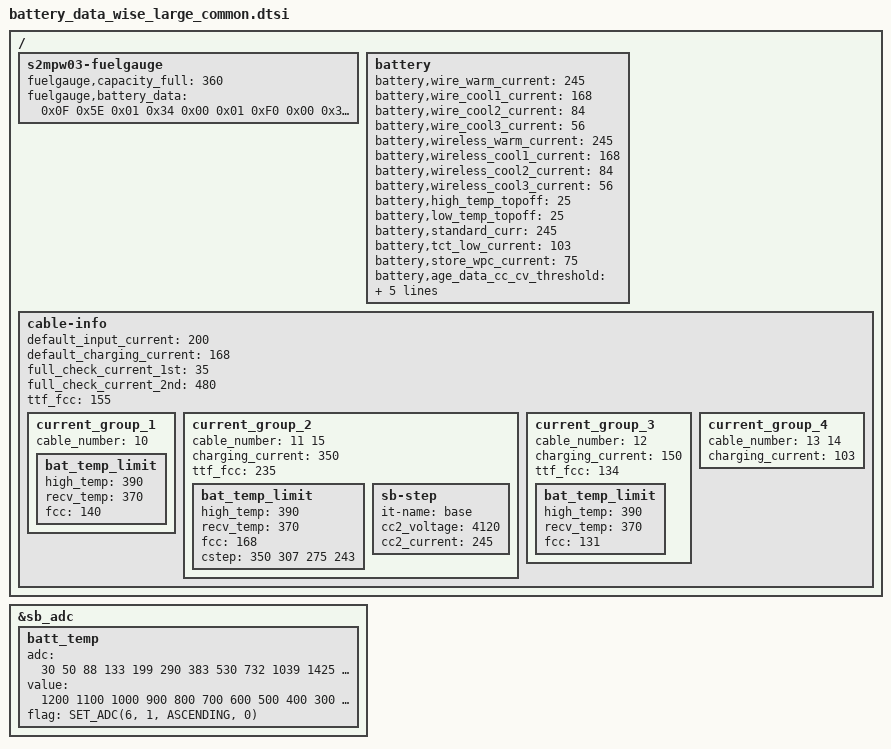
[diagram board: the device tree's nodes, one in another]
/*
 * SAMSUNG EXYNOS5515 board device tree source
 *
 * Copyright (c) 2021 Samsung Electronics Co., Ltd.
 *		http://www.samsung.com
 *
 * This program is free software; you can redistribute it and/or modify
 * it under the terms of the GNU General Public License version 2 as
 * published by the Free Software Foundation.
 */

#include "battery_data_wise_common.dtsi"

&sb_adc {
	batt_temp {
		adc = <
			30 50 88 133 199 290 383 530 732 1039
			1425 1871 2365 2853 3324
			>;

		value = <
			1200 1100 1000 900 800 700 600 500 400 300
			200 100 0 (-100) (-200)
			>;

		flag = <SET_ADC(6, 1, ASCENDING, 0)>;
	};
};

/ {
	fragment@battery {
		target-path = "/";
		__overlay__ {
			s2mpw03-fuelgauge {
				fuelgauge,capacity_full = <360>;

				fuelgauge,battery_data = /bits/ 8 <
					/* 4.42V */					
					/* table1 */
					0x0F 0x5E 0x01 0x34 0x00
					/* table2 */
					0x01 0xF0 0x00
					/* model_param1 */
					0x30 0x0B 0xD6 0x0A 0x7C 0x0A 0x33 0x0A 0xBB 0x09
					0x45 0x09 0xD5 0x08 0x6C 0x08 0x0A 0x08 0xA8 0x07
					0x3B 0x07 0xF8 0x06 0xBB 0x06 0x8F 0x06 0x6B 0x06
					0x4C 0x06 0x22 0x06 0xF7 0x05 0xC5 0x05 0x91 0x05
					0x6D 0x05 0xD8 0x02 0x66 0x08 0x00 0x08 0x9A 0x07
					0x33 0x07 0xCD 0x06 0x66 0x06 0x00 0x06 0x9A 0x05
					0x33 0x05 0xCD 0x04 0x66 0x04 0x00 0x04 0x9A 0x03
					0x33 0x03 0xCD 0x02 0x66 0x02 0x00 0x02 0x9A 0x01
					0x33 0x01 0xCD 0x00 0x66 0x00 0x00 0x00
					/* model_param2 */
					0xFF 0xFF 0xCB 0xCD 0xC9 0xC6 0xC4 0xC1 0xBF 0xBE
					0xC3 0xE4 0xC8 0xC8 0xC6 0xC0 0xBD 0xBE 0xC4 0xD7
					0xFF 0xCF

					/* 4.4V */
					/* table1 */
					0x0F 0x5B 0x01 0x34 0x00
					/* table2 */
					0x01 0xF0 0x00
					/* model_param1 */
					0x52 0x0B 0xDE 0x0A 0x69 0x0A 0x1C 0x0A 0xA4 0x09
					0x30 0x09 0xC1 0x08 0x5B 0x08 0xFC 0x07 0xA0 0x07
					0x34 0x07 0xEA 0x06 0xB5 0x06 0x8A 0x06 0x68 0x06
					0x4A 0x06 0x22 0x06 0xF7 0x05 0xC4 0x05 0x8D 0x05
					0x79 0x05 0xDA 0x02 0x66 0x08 0x00 0x08 0x9A 0x07
					0x33 0x07 0xCD 0x06 0x66 0x06 0x00 0x06 0x9A 0x05
					0x33 0x05 0xCD 0x04 0x66 0x04 0x00 0x04 0x9A 0x03
					0x33 0x03 0xCD 0x02 0x66 0x02 0x00 0x02 0x9A 0x01
					0x33 0x01 0xCD 0x00 0x66 0x00 0x00 0x00
					/* model_param2 */
					0xFF 0xFF 0xCB 0xCD 0xC9 0xC6 0xC4 0xC1 0xBF 0xBE
					0xC3 0xE4 0xC8 0xC8 0xC6 0xC0 0xBD 0xBE 0xC4 0xD7
					0xFF 0xCF

					/* 4.38V */
					/* table1 */
					0x0F 0x55 0x01 0x34 0x00
					/* table2 */
					0x01 0xF0 0x00
					/* model_param1 */
					0x27 0x0B 0xB4 0x0A 0x41 0x0A 0xF5 0x09 0x81 0x09
					0x10 0x09 0xA6 0x08 0x43 0x08 0xE7 0x07 0x89 0x07
					0x25 0x07 0xE0 0x06 0xAE 0x06 0x85 0x06 0x64 0x06
					0x45 0x06 0x1E 0x06 0xF3 0x05 0xC1 0x05 0x8C 0x05
					0x78 0x05 0xDA 0x02 0x66 0x08 0x00 0x08 0x9A 0x07
					0x33 0x07 0xCD 0x06 0x66 0x06 0x00 0x06 0x9A 0x05
					0x33 0x05 0xCD 0x04 0x66 0x04 0x00 0x04 0x9A 0x03
					0x33 0x03 0xCD 0x02 0x66 0x02 0x00 0x02 0x9A 0x01
					0x33 0x01 0xCD 0x00 0x66 0x00 0x00 0x00
					/* model_param2 */
					0xFF 0xFF 0xCB 0xCD 0xC9 0xC6 0xC4 0xC1 0xBF 0xBE
					0xC3 0xE4 0xC8 0xC8 0xC6 0xC0 0xBD 0xBE 0xC4 0xD7
					0xFF 0xCF

					/* 4.36V */
					/* table1 */
					0x0F 0x4E 0x01 0x34 0x00
					/* table2 */
					0x01 0xF0 0x00
					/* model_param1 */
					0xF9 0x0A 0x88 0x0A 0x16 0x0A 0xCC 0x09 0x5B 0x09
					0xEE 0x08 0x88 0x08 0x2A 0x08 0xD1 0x07 0x6F 0x07
					0x15 0x07 0xD6 0x06 0xA6 0x06 0x80 0x06 0x60 0x06
					0x41 0x06 0x1A 0x06 0xEF 0x05 0xBE 0x05 0x8C 0x05
					0x78 0x05 0xDA 0x02 0x66 0x08 0x00 0x08 0x9A 0x07
					0x33 0x07 0xCD 0x06 0x66 0x06 0x00 0x06 0x9A 0x05
					0x33 0x05 0xCD 0x04 0x66 0x04 0x00 0x04 0x9A 0x03
					0x33 0x03 0xCD 0x02 0x66 0x02 0x00 0x02 0x9A 0x01
					0x33 0x01 0xCD 0x00 0x66 0x00 0x00 0x00
					/* model_param2 */
					0xFF 0xFF 0xCB 0xCD 0xC9 0xC6 0xC4 0xC1 0xBF 0xBE
					0xC3 0xE4 0xC8 0xC8 0xC6 0xC0 0xBD 0xBE 0xC4 0xD7
					0xFF 0xCF

					/* 4.31V */
					/* table1 */
					0x0F 0x3F 0x01 0x34 0x00
					/* table2 */
					0x01 0xF0 0x00
					/* model_param1 */
					0x8E 0x0A 0x20 0x0A 0xB3 0x09 0x6F 0x09 0x06 0x09
					0xA3 0x08 0x47 0x08 0xF0 0x07 0x9B 0x07 0x36 0x07
					0xF1 0x06 0xBE 0x06 0x95 0x06 0x74 0x06 0x57 0x06
					0x37 0x06 0x11 0x06 0xE7 0x05 0xB7 0x05 0x8A 0x05
					0x78 0x05 0xDA 0x02 0x66 0x08 0x00 0x08 0x9A 0x07
					0x33 0x07 0xCD 0x06 0x66 0x06 0x00 0x06 0x9A 0x05
					0x33 0x05 0xCD 0x04 0x66 0x04 0x00 0x04 0x9A 0x03
					0x33 0x03 0xCD 0x02 0x66 0x02 0x00 0x02 0x9A 0x01
					0x33 0x01 0xCD 0x00 0x66 0x00 0x00 0x00
					/* model_param2 */
					0xFF 0xFF 0xCB 0xCD 0xC9 0xC6 0xC4 0xC1 0xBF 0xBE
					0xC3 0xE4 0xC8 0xC8 0xC6 0xC0 0xBD 0xBE 0xC4 0xD7
					0xFF 0xCF
				>;
			};

			battery {
				battery,wire_warm_current = <245>;	/* 0.36C */
				battery,wire_cool1_current = <168>;	/* Not used */
				battery,wire_cool2_current = <84>;	/* 0.24C */
				battery,wire_cool3_current = <56>;	/* 0.16C */

				battery,wireless_warm_current = <245>;	/* 0.24C */
				battery,wireless_cool1_current = <168>;	/* Not used */
				battery,wireless_cool2_current = <84>;	/* 0.24C */
				battery,wireless_cool3_current = <56>;	/* 0.16C */

				battery,high_temp_topoff = <25>;	/* 0.05C */
				battery,low_temp_topoff = <25>;		/* 0.05C */

				battery,standard_curr = <245>;
				battery,tct_low_current = <103>;
				battery,store_wpc_current = <75>;
				battery,age_data_cc_cv_threshold = <4150 4150 4150 4150 4150>;

				battery,battery_full_capacity = <360>;
				battery,ttf_capacity = <360>;
				battery,cv_data = <
					259	800	2280
					242	810	2220
					230	820	2159
					216	830	2099
					202	840	2039
					186	850	1979
					174	860	1919
					165	870	1860
					156	880	1800
					138	890	1677
					127	900	1620
					119	910	1499
					112	920	1380
					104	930	1260
					97	940	1140
					91	950	1020
					78	960	833
					71	970	713
					60	980	480
					50	990	240
					42	1000	0
					>;
			};

			/* sec_battery_cable
			 *   0	UNKNOWN,
			 *   1	NONE,
			 *   2	TA,
			 *   3	USB,
			 *   4	UARTOFF,
			 *   5	RESERVED,
			 *   6	RESERVED,
			 *   7	RESERVED,
			 *   8	RESERVED,
			 *   9	RESERVED,
			 *  10	WRL,
			 *  11	INBOX_WRL,
			 *  12	D2D_WRL,
			 *  13	INCOMP_WRL,
			 *  14	ERR_WRL,
			 *  15	FM_WRL,
			 */
			cable-info {
				default_input_current = <200>;
				default_charging_current = <168>;	/* 0.48C */
				full_check_current_1st = <35>;
				full_check_current_2nd = <480>;	/* time: 8min */
				ttf_fcc = <155>;

				current_group_1 {
					cable_number = <10>;

					bat_temp_limit {
						high_temp = <390>;
						recv_temp = <370>;
						fcc = <140>;
					};
				};

				current_group_2 {
					cable_number = <11 15>;
					charging_current = <350>;	/* 1C */
					ttf_fcc = <235>;

					bat_temp_limit {
						high_temp = <390>;
						recv_temp = <370>;
						fcc = <168>;
						cstep = <350 307 275 243>; /* 1C 0.9C 0.8C 0.7C */
					};

					sb-step {
						it-name = "base";

						cc2_voltage = <4120>;
						cc2_current = <245>;	/* 0.7C */
					};
				};

				current_group_3 {
					cable_number = <12>;
					charging_current = <150>;
					ttf_fcc = <134>;

					bat_temp_limit {
						high_temp = <390>;
						recv_temp = <370>;
						fcc = <131>;
					};
				};

				current_group_4 {
					cable_number = <13 14>;
					charging_current = <103>;
				};
			};
		};
	};
};

